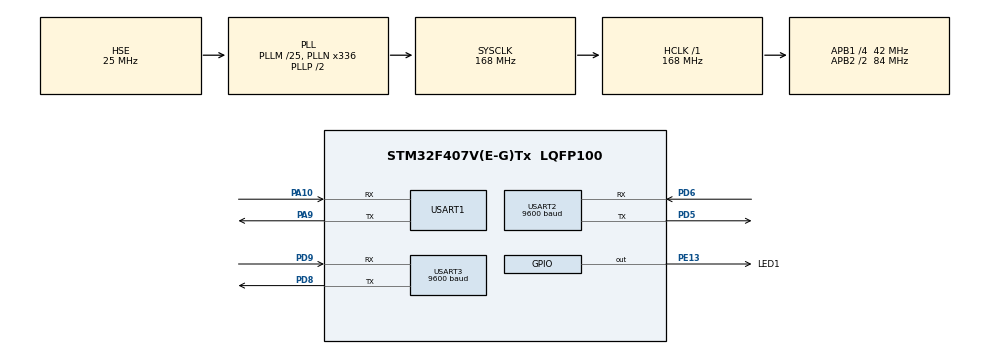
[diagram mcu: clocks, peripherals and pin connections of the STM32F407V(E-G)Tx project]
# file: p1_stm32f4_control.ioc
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Dma.Request0=USART1_RX
Dma.Request1=USART1_TX
Dma.Request2=USART2_RX
Dma.Request3=USART2_TX
Dma.Request4=USART3_RX
Dma.Request5=USART3_TX
Dma.USART1_RX.0.Direction=DMA_PERIPH_TO_MEMORY
Dma.USART1_RX.0.FIFOMode=DMA_FIFOMODE_DISABLE
Dma.USART1_RX.0.Instance=DMA2_Stream5
Dma.USART1_RX.0.MemDataAlignment=DMA_MDATAALIGN_BYTE
Dma.USART1_RX.0.MemInc=DMA_MINC_ENABLE
Dma.USART1_RX.0.Mode=DMA_CIRCULAR
Dma.USART1_RX.0.PeriphDataAlignment=DMA_PDATAALIGN_BYTE
Dma.USART1_RX.0.PeriphInc=DMA_PINC_DISABLE
Dma.USART1_RX.0.Priority=DMA_PRIORITY_LOW
Dma.USART1_TX.1.Direction=DMA_MEMORY_TO_PERIPH
Dma.USART1_TX.1.FIFOMode=DMA_FIFOMODE_DISABLE
Dma.USART1_TX.1.Instance=DMA2_Stream7
Dma.USART1_TX.1.MemDataAlignment=DMA_MDATAALIGN_BYTE
Dma.USART1_TX.1.MemInc=DMA_MINC_ENABLE
Dma.USART1_TX.1.Mode=DMA_NORMAL
Dma.USART1_TX.1.PeriphDataAlignment=DMA_PDATAALIGN_BYTE
Dma.USART1_TX.1.PeriphInc=DMA_PINC_DISABLE
Dma.USART1_TX.1.Priority=DMA_PRIORITY_LOW
Dma.USART2_RX.2.Direction=DMA_PERIPH_TO_MEMORY
Dma.USART2_RX.2.FIFOMode=DMA_FIFOMODE_DISABLE
Dma.USART2_RX.2.Instance=DMA1_Stream5
Dma.USART2_RX.2.MemDataAlignment=DMA_MDATAALIGN_BYTE
Dma.USART2_RX.2.MemInc=DMA_MINC_ENABLE
Dma.USART2_RX.2.Mode=DMA_NORMAL
Dma.USART2_RX.2.PeriphDataAlignment=DMA_PDATAALIGN_BYTE
Dma.USART2_RX.2.PeriphInc=DMA_PINC_DISABLE
Dma.USART2_RX.2.Priority=DMA_PRIORITY_LOW
Dma.USART2_TX.3.Direction=DMA_MEMORY_TO_PERIPH
Dma.USART2_TX.3.FIFOMode=DMA_FIFOMODE_DISABLE
Dma.USART2_TX.3.Instance=DMA1_Stream6
Dma.USART2_TX.3.MemDataAlignment=DMA_MDATAALIGN_BYTE
Dma.USART2_TX.3.MemInc=DMA_MINC_ENABLE
Dma.USART2_TX.3.Mode=DMA_NORMAL
Dma.USART2_TX.3.PeriphDataAlignment=DMA_PDATAALIGN_BYTE
Dma.USART2_TX.3.PeriphInc=DMA_PINC_DISABLE
Dma.USART2_TX.3.Priority=DMA_PRIORITY_LOW
Dma.USART3_RX.4.Direction=DMA_PERIPH_TO_MEMORY
Dma.USART3_RX.4.FIFOMode=DMA_FIFOMODE_DISABLE
Dma.USART3_RX.4.Instance=DMA1_Stream1
Dma.USART3_RX.4.MemDataAlignment=DMA_MDATAALIGN_BYTE
Dma.USART3_RX.4.MemInc=DMA_MINC_ENABLE
Dma.USART3_RX.4.Mode=DMA_NORMAL
Dma.USART3_RX.4.PeriphDataAlignment=DMA_PDATAALIGN_BYTE
Dma.USART3_RX.4.PeriphInc=DMA_PINC_DISABLE
Dma.USART3_RX.4.Priority=DMA_PRIORITY_LOW
Dma.USART3_TX.5.Direction=DMA_MEMORY_TO_PERIPH
Dma.USART3_TX.5.FIFOMode=DMA_FIFOMODE_DISABLE
Dma.USART3_TX.5.Instance=DMA1_Stream3
Dma.USART3_TX.5.MemDataAlignment=DMA_MDATAALIGN_BYTE
Dma.USART3_TX.5.MemInc=DMA_MINC_ENABLE
Dma.USART3_TX.5.Mode=DMA_NORMAL
Dma.USART3_TX.5.PeriphDataAlignment=DMA_PDATAALIGN_BYTE
Dma.USART3_TX.5.PeriphInc=DMA_PINC_DISABLE
Dma.USART3_TX.5.Priority=DMA_PRIORITY_LOW
FREERTOS.Tasks01=defaultTask,24,256,StartDefaultTask,Default,NULL,Dynamic,NULL,NULL
Mcu.Family=STM32F4
Mcu.Name=STM32F407V(E-G)Tx
Mcu.Package=LQFP100
NVIC.DMA1_Stream1_IRQn=true\:5\:0\:false\:false\:true\:true\:false\:true\:true
NVIC.DMA1_Stream3_IRQn=true\:5\:0\:false\:false\:true\:true\:false\:true\:true
NVIC.DMA1_Stream5_IRQn=true\:5\:0\:false\:false\:true\:true\:false\:true\:true
NVIC.DMA1_Stream6_IRQn=true\:5\:0\:false\:false\:true\:true\:false\:true\:true
NVIC.DMA2_Stream5_IRQn=true\:5\:0\:false\:false\:true\:false\:false\:true\:true
NVIC.DMA2_Stream7_IRQn=true\:5\:0\:false\:false\:true\:true\:false\:true\:true
NVIC.PriorityGroup=NVIC_PRIORITYGROUP_4
NVIC.USART1_IRQn=true\:5\:0\:false\:false\:true\:true\:true\:true\:true
NVIC.USART2_IRQn=true\:5\:0\:true\:false\:true\:true\:true\:true\:true
NVIC.USART3_IRQn=true\:5\:0\:false\:false\:true\:true\:true\:true\:true
PA10.Mode=Asynchronous
PA10.Signal=USART1_RX
PA13.Mode=Serial_Wire
PA13.Signal=SYS_JTMS-SWDIO
PA14.Mode=Serial_Wire
PA14.Signal=SYS_JTCK-SWCLK
PA9.Mode=Asynchronous
PA9.Signal=USART1_TX
PD5.Mode=Asynchronous
PD5.Signal=USART2_TX
PD6.Mode=Asynchronous
PD6.Signal=USART2_RX
PD8.Mode=Asynchronous
PD8.Signal=USART3_TX
PD9.Mode=Asynchronous
PD9.Signal=USART3_RX
PE13.GPIO_Label=LED1
PE13.PinState=GPIO_PIN_SET
PE13.Signal=GPIO_Output
PH0-OSC_IN.Mode=HSE-External-Oscillator
PH0-OSC_IN.Signal=RCC_OSC_IN
PH1-OSC_OUT.Mode=HSE-External-Oscillator
PH1-OSC_OUT.Signal=RCC_OSC_OUT
ProjectManager.HeapSize=0x200
ProjectManager.StackSize=0x400
ProjectManager.TargetToolchain=STM32CubeIDE
RCC.48MHZClocksFreq_Value=84000000
RCC.AHBFreq_Value=168000000
RCC.APB1CLKDivider=RCC_HCLK_DIV4
RCC.APB1Freq_Value=42000000
RCC.APB1TimFreq_Value=84000000
RCC.APB2CLKDivider=RCC_HCLK_DIV2
RCC.APB2Freq_Value=84000000
RCC.APB2TimFreq_Value=168000000
RCC.CortexFreq_Value=168000000
RCC.HCLKFreq_Value=168000000
RCC.HSE_VALUE=25000000
RCC.HSI_VALUE=16000000
RCC.LSE_VALUE=32768
RCC.PLLM=25
RCC.PLLN=336
RCC.PLLSourceVirtual=RCC_PLLSOURCE_HSE
RCC.SYSCLKFreq_VALUE=168000000
RCC.SYSCLKSource=RCC_SYSCLKSOURCE_PLLCLK
RCC.VCOOutputFreq_Value=336000000
USART1.VirtualMode=VM_ASYNC
USART2.BaudRate=9600
USART2.VirtualMode=VM_ASYNC
USART3.BaudRate=9600
USART3.VirtualMode=VM_ASYNC
VP_FREERTOS_VS_CMSIS_V2.Mode=CMSIS_V2
board=custom

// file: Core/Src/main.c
/* USER CODE BEGIN Header */
/**
 ******************************************************************************
 * @file           : main.c
 * @brief          : Main program body
 ******************************************************************************
 * @attention
 *
 * Copyright (c) 2026 STMicroelectronics.
 * All rights reserved.
 *
 * This software is licensed under terms that can be found in the LICENSE file
 * in the root directory of this software component.
 * If no LICENSE file comes with this software, it is provided AS-IS.
 *
 ******************************************************************************
 */
/* USER CODE END Header */
#include "main.h"
#include "cmsis_os.h"

/* USER CODE BEGIN Includes */
// #include "user_task.h"
#include "hardware.h"
/* USER CODE END Includes */

UART_HandleTypeDef huart1;
UART_HandleTypeDef huart2;
UART_HandleTypeDef huart3;
DMA_HandleTypeDef hdma_usart1_rx;
DMA_HandleTypeDef hdma_usart1_tx;
DMA_HandleTypeDef hdma_usart2_rx;
DMA_HandleTypeDef hdma_usart2_tx;
DMA_HandleTypeDef hdma_usart3_rx;
DMA_HandleTypeDef hdma_usart3_tx;

/* Definitions for defaultTask */
osThreadId_t defaultTaskHandle;
const osThreadAttr_t defaultTask_attributes = {
  .name = "defaultTask",
  .stack_size = 256 * 4,
  .priority = (osPriority_t) osPriorityNormal,
};

void SystemClock_Config(void);
static void MX_GPIO_Init(void);
static void MX_DMA_Init(void);
static void MX_USART1_UART_Init(void);
static void MX_USART2_UART_Init(void);
static void MX_USART3_UART_Init(void);
void StartDefaultTask(void *argument);

int main(void)
{

  /* MCU Configuration--------------------------------------------------------*/

  /* Reset of all peripherals, Initializes the Flash interface and the Systick. */
  HAL_Init();

  /* Configure the system clock */
  SystemClock_Config();

  /* Initialize all configured peripherals */
  MX_GPIO_Init();
  MX_DMA_Init();
  MX_USART1_UART_Init();
  MX_USART2_UART_Init();
  MX_USART3_UART_Init();
  /* USER CODE BEGIN 2 */

  HAL_UART_Transmit(&huart1, (uint8_t *)"Hello\r\n", 7, HAL_MAX_DELAY);
  HAL_Delay(1000);
  /* USER CODE END 2 */

  /* Init scheduler */
  osKernelInitialize();

  /* Create the thread(s) */
  /* creation of defaultTask */
  defaultTaskHandle = osThreadNew(StartDefaultTask, NULL, &defaultTask_attributes);

  /* USER CODE BEGIN RTOS_THREADS */
  init_user_task();

  /* USER CODE END RTOS_THREADS */

  /* Start scheduler */
  osKernelStart();

  /* We should never get here as control is now taken by the scheduler */

  /* Infinite loop */
  while (1)
  {

  }
}

void SystemClock_Config(void)
{
  RCC_OscInitTypeDef RCC_OscInitStruct = {0};
  RCC_ClkInitTypeDef RCC_ClkInitStruct = {0};

  /** Configure the main internal regulator output voltage
  */
  __HAL_RCC_PWR_CLK_ENABLE();
  __HAL_PWR_VOLTAGESCALING_CONFIG(PWR_REGULATOR_VOLTAGE_SCALE1);

  /** Initializes the RCC Oscillators according to the specified parameters
  * in the RCC_OscInitTypeDef structure.
  */
  RCC_OscInitStruct.OscillatorType = RCC_OSCILLATORTYPE_HSE;
  RCC_OscInitStruct.HSEState = RCC_HSE_ON;
  RCC_OscInitStruct.PLL.PLLState = RCC_PLL_ON;
  RCC_OscInitStruct.PLL.PLLSource = RCC_PLLSOURCE_HSE;
  RCC_OscInitStruct.PLL.PLLM = 25;
  RCC_OscInitStruct.PLL.PLLN = 336;
  RCC_OscInitStruct.PLL.PLLP = RCC_PLLP_DIV2;
  RCC_OscInitStruct.PLL.PLLQ = 4;
  if (HAL_RCC_OscConfig(&RCC_OscInitStruct) != HAL_OK)
  {
    Error_Handler();
  }

  /** Initializes the CPU, AHB and APB buses clocks
  */
  RCC_ClkInitStruct.ClockType = RCC_CLOCKTYPE_HCLK|RCC_CLOCKTYPE_SYSCLK
                              |RCC_CLOCKTYPE_PCLK1|RCC_CLOCKTYPE_PCLK2;
  RCC_ClkInitStruct.SYSCLKSource = RCC_SYSCLKSOURCE_PLLCLK;
  RCC_ClkInitStruct.AHBCLKDivider = RCC_SYSCLK_DIV1;
  RCC_ClkInitStruct.APB1CLKDivider = RCC_HCLK_DIV4;
  RCC_ClkInitStruct.APB2CLKDivider = RCC_HCLK_DIV2;

  if (HAL_RCC_ClockConfig(&RCC_ClkInitStruct, FLASH_LATENCY_5) != HAL_OK)
  {
    Error_Handler();
  }
}

static void MX_USART1_UART_Init(void)
{

  huart1.Instance = USART1;
  huart1.Init.BaudRate = 115200;
  huart1.Init.WordLength = UART_WORDLENGTH_8B;
  huart1.Init.StopBits = UART_STOPBITS_1;
  huart1.Init.Parity = UART_PARITY_NONE;
  huart1.Init.Mode = UART_MODE_TX_RX;
  huart1.Init.HwFlowCtl = UART_HWCONTROL_NONE;
  huart1.Init.OverSampling = UART_OVERSAMPLING_16;
  if (HAL_UART_Init(&huart1) != HAL_OK)
  {
    Error_Handler();
  }

}

static void MX_USART2_UART_Init(void)
{

  huart2.Instance = USART2;
  huart2.Init.BaudRate = 9600;
  huart2.Init.WordLength = UART_WORDLENGTH_8B;
  huart2.Init.StopBits = UART_STOPBITS_1;
  huart2.Init.Parity = UART_PARITY_NONE;
  huart2.Init.Mode = UART_MODE_TX_RX;
  huart2.Init.HwFlowCtl = UART_HWCONTROL_NONE;
  huart2.Init.OverSampling = UART_OVERSAMPLING_16;
  if (HAL_UART_Init(&huart2) != HAL_OK)
  {
    Error_Handler();
  }

}

static void MX_USART3_UART_Init(void)
{

  huart3.Instance = USART3;
  huart3.Init.BaudRate = 9600;
  huart3.Init.WordLength = UART_WORDLENGTH_8B;
  huart3.Init.StopBits = UART_STOPBITS_1;
  huart3.Init.Parity = UART_PARITY_NONE;
  huart3.Init.Mode = UART_MODE_TX_RX;
  huart3.Init.HwFlowCtl = UART_HWCONTROL_NONE;
  huart3.Init.OverSampling = UART_OVERSAMPLING_16;
  if (HAL_UART_Init(&huart3) != HAL_OK)
  {
    Error_Handler();
  }

}

static void MX_DMA_Init(void)
{

  /* DMA controller clock enable */
  __HAL_RCC_DMA2_CLK_ENABLE();
  __HAL_RCC_DMA1_CLK_ENABLE();

  /* DMA interrupt init */
  /* DMA1_Stream1_IRQn interrupt configuration */
  HAL_NVIC_SetPriority(DMA1_Stream1_IRQn, 5, 0);
  HAL_NVIC_EnableIRQ(DMA1_Stream1_IRQn);
  /* DMA1_Stream3_IRQn interrupt configuration */
  HAL_NVIC_SetPriority(DMA1_Stream3_IRQn, 5, 0);
  HAL_NVIC_EnableIRQ(DMA1_Stream3_IRQn);
  /* DMA1_Stream5_IRQn interrupt configuration */
  HAL_NVIC_SetPriority(DMA1_Stream5_IRQn, 5, 0);
  HAL_NVIC_EnableIRQ(DMA1_Stream5_IRQn);
  /* DMA1_Stream6_IRQn interrupt configuration */
  HAL_NVIC_SetPriority(DMA1_Stream6_IRQn, 5, 0);
  HAL_NVIC_EnableIRQ(DMA1_Stream6_IRQn);
  /* DMA2_Stream5_IRQn interrupt configuration */
  HAL_NVIC_SetPriority(DMA2_Stream5_IRQn, 5, 0);
  HAL_NVIC_EnableIRQ(DMA2_Stream5_IRQn);
  /* DMA2_Stream7_IRQn interrupt configuration */
  HAL_NVIC_SetPriority(DMA2_Stream7_IRQn, 5, 0);
  HAL_NVIC_EnableIRQ(DMA2_Stream7_IRQn);

}

static void MX_GPIO_Init(void)
{
  GPIO_InitTypeDef GPIO_InitStruct = {0};

  /* GPIO Ports Clock Enable */
  __HAL_RCC_GPIOH_CLK_ENABLE();
  __HAL_RCC_GPIOE_CLK_ENABLE();
  __HAL_RCC_GPIOD_CLK_ENABLE();
  __HAL_RCC_GPIOA_CLK_ENABLE();

  /*Configure GPIO pin Output Level */
  HAL_GPIO_WritePin(LED1_GPIO_Port, LED1_Pin, GPIO_PIN_SET);

  /*Configure GPIO pin : LED1_Pin */
  GPIO_InitStruct.Pin = LED1_Pin;
  GPIO_InitStruct.Mode = GPIO_MODE_OUTPUT_PP;
  GPIO_InitStruct.Pull = GPIO_NOPULL;
  GPIO_InitStruct.Speed = GPIO_SPEED_FREQ_LOW;
  HAL_GPIO_Init(LED1_GPIO_Port, &GPIO_InitStruct);

}

void StartDefaultTask(void *argument)
{
  /* USER CODE BEGIN 5 */
  /* Infinite loop */
  for (;;)
  {

    osDelay(500);
  }
  /* USER CODE END 5 */
}

void Error_Handler(void)
{
  __disable_irq();
  while (1)
  {
  }
}
